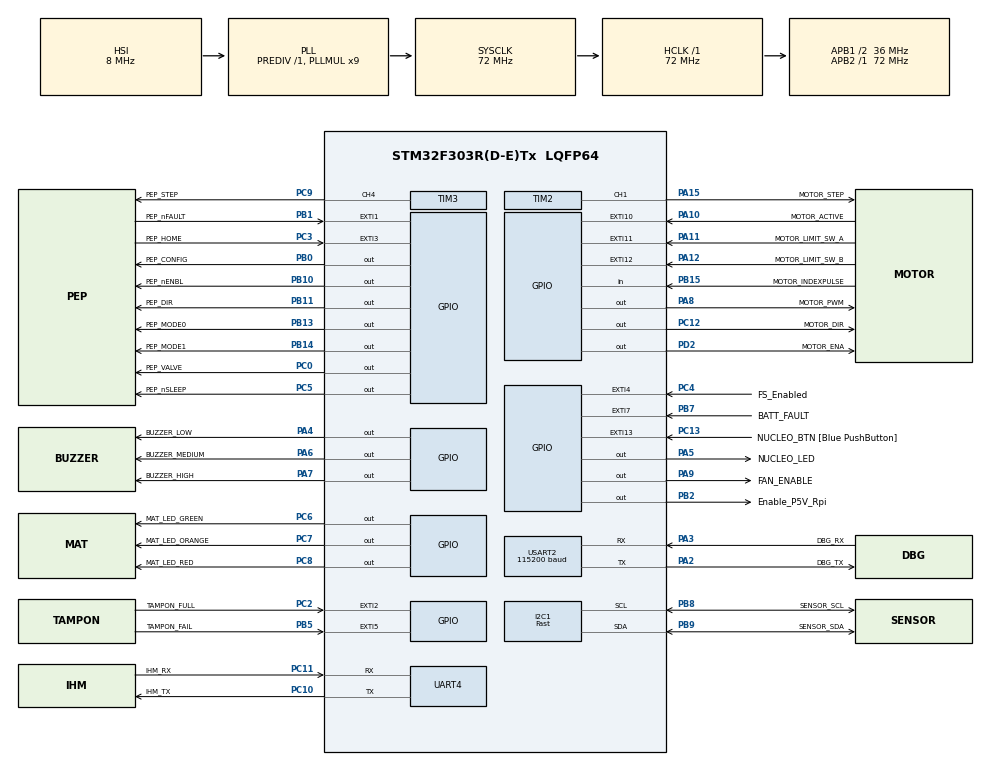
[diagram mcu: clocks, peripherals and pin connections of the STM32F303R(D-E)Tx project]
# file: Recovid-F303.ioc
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Dma.I2C1_RX.0.Direction=DMA_PERIPH_TO_MEMORY
Dma.I2C1_RX.0.Instance=DMA1_Channel7
Dma.I2C1_RX.0.MemDataAlignment=DMA_MDATAALIGN_BYTE
Dma.I2C1_RX.0.MemInc=DMA_MINC_ENABLE
Dma.I2C1_RX.0.Mode=DMA_NORMAL
Dma.I2C1_RX.0.PeriphDataAlignment=DMA_PDATAALIGN_BYTE
Dma.I2C1_RX.0.PeriphInc=DMA_PINC_DISABLE
Dma.I2C1_RX.0.Priority=DMA_PRIORITY_LOW
Dma.I2C1_TX.1.Direction=DMA_MEMORY_TO_PERIPH
Dma.I2C1_TX.1.Instance=DMA1_Channel6
Dma.I2C1_TX.1.MemDataAlignment=DMA_MDATAALIGN_BYTE
Dma.I2C1_TX.1.MemInc=DMA_MINC_ENABLE
Dma.I2C1_TX.1.Mode=DMA_NORMAL
Dma.I2C1_TX.1.PeriphDataAlignment=DMA_PDATAALIGN_BYTE
Dma.I2C1_TX.1.PeriphInc=DMA_PINC_DISABLE
Dma.I2C1_TX.1.Priority=DMA_PRIORITY_LOW
Dma.Request0=I2C1_RX
Dma.Request1=I2C1_TX
Dma.Request2=TIM3_CH4/UP
Dma.Request3=UART4_TX
Dma.Request4=TIM2_UP
Dma.TIM2_UP.4.Direction=DMA_MEMORY_TO_PERIPH
Dma.TIM2_UP.4.Instance=DMA1_Channel2
Dma.TIM2_UP.4.MemDataAlignment=DMA_MDATAALIGN_HALFWORD
Dma.TIM2_UP.4.MemInc=DMA_MINC_ENABLE
Dma.TIM2_UP.4.Mode=DMA_NORMAL
Dma.TIM2_UP.4.PeriphDataAlignment=DMA_PDATAALIGN_WORD
Dma.TIM2_UP.4.PeriphInc=DMA_PINC_DISABLE
Dma.TIM2_UP.4.Priority=DMA_PRIORITY_HIGH
Dma.TIM3_CH4/UP.2.Direction=DMA_PERIPH_TO_MEMORY
Dma.TIM3_CH4/UP.2.Instance=DMA1_Channel3
Dma.TIM3_CH4/UP.2.MemDataAlignment=DMA_MDATAALIGN_HALFWORD
Dma.TIM3_CH4/UP.2.MemInc=DMA_MINC_ENABLE
Dma.TIM3_CH4/UP.2.Mode=DMA_NORMAL
Dma.TIM3_CH4/UP.2.PeriphDataAlignment=DMA_PDATAALIGN_HALFWORD
Dma.TIM3_CH4/UP.2.PeriphInc=DMA_PINC_DISABLE
Dma.TIM3_CH4/UP.2.Priority=DMA_PRIORITY_LOW
Dma.UART4_TX.3.Direction=DMA_MEMORY_TO_PERIPH
Dma.UART4_TX.3.Instance=DMA2_Channel5
Dma.UART4_TX.3.MemDataAlignment=DMA_MDATAALIGN_BYTE
Dma.UART4_TX.3.MemInc=DMA_MINC_ENABLE
Dma.UART4_TX.3.Mode=DMA_NORMAL
Dma.UART4_TX.3.PeriphDataAlignment=DMA_PDATAALIGN_BYTE
Dma.UART4_TX.3.PeriphInc=DMA_PINC_DISABLE
Dma.UART4_TX.3.Priority=DMA_PRIORITY_LOW
I2C1.I2C_Speed_Mode=I2C_Fast
I2C1.Timing=0x0000020B
Mcu.Family=STM32F3
Mcu.Name=STM32F303R(D-E)Tx
Mcu.Package=LQFP64
Mcu.UserConstants=MOTOR_PULSE_WIDTH_US,10;PEP_PULSE_WIDTH_US,10
NVIC.DMA1_Channel2_IRQn=true\:0\:5\:false\:false\:true\:false\:true
NVIC.DMA1_Channel3_IRQn=true\:0\:0\:false\:false\:true\:false\:true
NVIC.DMA1_Channel6_IRQn=true\:0\:0\:false\:false\:true\:false\:true
NVIC.DMA1_Channel7_IRQn=true\:0\:0\:false\:false\:true\:false\:true
NVIC.DMA2_Channel5_IRQn=true\:0\:0\:false\:false\:true\:false\:true
NVIC.EXTI15_10_IRQn=true\:0\:0\:false\:false\:true\:true\:true
NVIC.EXTI1_IRQn=true\:0\:0\:false\:false\:true\:true\:true
NVIC.EXTI2_TSC_IRQn=true\:0\:0\:false\:false\:true\:true\:true
NVIC.EXTI3_IRQn=true\:0\:0\:false\:false\:true\:true\:true
NVIC.EXTI4_IRQn=true\:0\:0\:false\:false\:true\:true\:true
NVIC.EXTI9_5_IRQn=true\:0\:0\:false\:false\:true\:true\:true
NVIC.I2C1_ER_IRQn=true\:0\:0\:false\:false\:true\:true\:true
NVIC.I2C1_EV_IRQn=true\:0\:0\:false\:false\:true\:true\:true
NVIC.PriorityGroup=NVIC_PRIORITYGROUP_0
NVIC.TIM1_BRK_TIM15_IRQn=true\:0\:0\:false\:false\:true\:true\:true
NVIC.TIM2_IRQn=true\:0\:5\:false\:false\:true\:true\:true
NVIC.TIM3_IRQn=true\:0\:0\:false\:false\:true\:true\:true
NVIC.TIM7_IRQn=true\:0\:0\:false\:false\:true\:true\:true
NVIC.UART4_IRQn=true\:0\:0\:false\:false\:true\:true\:true
NVIC.USART2_IRQn=true\:0\:0\:false\:false\:true\:true\:true
PA10.GPIO_Label=MOTOR_ACTIVE
PA10.GPIO_ModeDefaultEXTI=GPIO_MODE_IT_RISING_FALLING
PA10.Signal=GPXTI10
PA11.GPIO_Label=MOTOR_LIMIT_SW_A
PA11.GPIO_ModeDefaultEXTI=GPIO_MODE_IT_RISING_FALLING
PA11.Signal=GPXTI11
PA12.GPIO_Label=MOTOR_LIMIT_SW_B
PA12.GPIO_ModeDefaultEXTI=GPIO_MODE_IT_RISING_FALLING
PA12.Signal=GPXTI12
PA13.GPIO_Label=TMS
PA13.Mode=Trace_Asynchronous_SW
PA13.Signal=SYS_JTMS-SWDIO
PA14.GPIO_Label=TCK
PA14.Mode=Trace_Asynchronous_SW
PA14.Signal=SYS_JTCK-SWCLK
PA15.GPIO_Label=MOTOR_STEP
PA15.Signal=S_TIM2_CH1_ETR
PA2.GPIO_Label=DBG_TX
PA2.GPIO_Mode=GPIO_MODE_AF_PP
PA2.GPIO_PuPd=GPIO_NOPULL
PA2.GPIO_Speed=GPIO_SPEED_FREQ_LOW
PA2.Mode=Asynchronous
PA2.Signal=USART2_TX
PA3.GPIO_Label=DBG_RX
PA3.GPIO_Mode=GPIO_MODE_AF_PP
PA3.GPIO_PuPd=GPIO_NOPULL
PA3.GPIO_Speed=GPIO_SPEED_FREQ_LOW
PA3.Mode=Asynchronous
PA3.Signal=USART2_RX
PA4.GPIO_Label=BUZZER_LOW
PA4.Signal=GPIO_Output
PA5.GPIO_Label=NUCLEO_LED
PA5.Signal=GPIO_Output
PA6.GPIO_Label=BUZZER_MEDIUM
PA6.Signal=GPIO_Output
PA7.GPIO_Label=BUZZER_HIGH
PA7.Signal=GPIO_Output
PA8.GPIO_Label=MOTOR_PWM
PA8.Signal=GPIO_Output
PA9.GPIO_Label=FAN_ENABLE
PA9.Signal=GPIO_Output
PB0.GPIO_Label=PEP_CONFIG
PB0.Signal=GPIO_Output
PB1.GPIO_Label=PEP_nFAULT
PB1.Signal=GPXTI1
PB10.GPIO_Label=PEP_nENBL
PB10.Signal=GPIO_Output
PB11.GPIO_Label=PEP_DIR
PB11.Signal=GPIO_Output
PB13.GPIO_Label=PEP_MODE0
PB13.Signal=GPIO_Output
PB14.GPIO_Label=PEP_MODE1
PB14.Signal=GPIO_Output
PB15.GPIO_Label=MOTOR_INDEXPULSE
PB15.Signal=GPIO_Input
PB2.GPIO_Label=Enable_P5V_Rpi
PB2.Signal=GPIO_Output
PB3.GPIO_Label=SWO
PB3.Mode=Trace_Asynchronous_SW
PB3.Signal=SYS_JTDO-TRACESWO
PB5.GPIO_Label=TAMPON_FAIL
PB5.Signal=GPXTI5
PB7.GPIO_Label=BATT_FAULT
PB7.Signal=GPXTI7
PB8.GPIO_Label=SENSOR_SCL
PB8.Mode=I2C
PB8.Signal=I2C1_SCL
PB9.GPIO_Label=SENSOR_SDA
PB9.Mode=I2C
PB9.Signal=I2C1_SDA
PC0.GPIO_Label=PEP_VALVE
PC0.Signal=GPIO_Output
PC10.GPIO_Label=IHM_TX
PC10.Mode=Asynchronous
PC10.Signal=UART4_TX
PC11.GPIO_Label=IHM_RX
PC11.Mode=Asynchronous
PC11.Signal=UART4_RX
PC12.GPIO_Label=MOTOR_DIR
PC12.Signal=GPIO_Output
PC13.GPIO_Label=NUCLEO_BTN [Blue PushButton]
PC13.GPIO_ModeDefaultEXTI=GPIO_MODE_IT_FALLING
PC13.Signal=GPXTI13
PC14-OSC32_IN.Mode=LSE-External-Oscillator
PC14-OSC32_IN.Signal=RCC_OSC32_IN
PC15-OSC32_OUT.Mode=LSE-External-Oscillator
PC15-OSC32_OUT.Signal=RCC_OSC32_OUT
PC2.GPIO_Label=TAMPON_FULL
PC2.Signal=GPXTI2
PC3.GPIO_Label=PEP_HOME
PC3.GPIO_ModeDefaultEXTI=GPIO_MODE_IT_RISING_FALLING
PC3.Signal=GPXTI3
PC4.GPIO_Label=FS_Enabled
PC4.Signal=GPXTI4
PC5.GPIO_Label=PEP_nSLEEP
PC5.Signal=GPIO_Output
PC6.GPIO_Label=MAT_LED_GREEN
PC6.Signal=GPIO_Output
PC7.GPIO_Label=MAT_LED_ORANGE
PC7.Signal=GPIO_Output
PC8.GPIO_Label=MAT_LED_RED
PC8.Signal=GPIO_Output
PC9.GPIO_Label=PEP_STEP
PC9.Signal=S_TIM3_CH4
PD2.GPIO_Label=MOTOR_ENA
PD2.Signal=GPIO_Output
PF0-OSC_IN.Mode=HSE-External-Clock-Source
PF0-OSC_IN.Signal=RCC_OSC_IN
PF1-OSC_OUT.Signal=RCC_OSC_OUT
ProjectManager.HeapSize=0x200
ProjectManager.StackSize=0x400
ProjectManager.TargetToolchain=STM32CubeIDE
RCC.AHBFreq_Value=72000000
RCC.APB1CLKDivider=RCC_HCLK_DIV2
RCC.APB1Freq_Value=36000000
RCC.APB1TimFreq_Value=72000000
RCC.APB2Freq_Value=72000000
RCC.APB2TimFreq_Value=72000000
RCC.CortexFreq_Value=72000000
RCC.HCLKFreq_Value=72000000
RCC.HSE_VALUE=8000000
RCC.HSI_VALUE=8000000
RCC.PLLM=8
RCC.PLLMUL=RCC_PLL_MUL9
RCC.PLLN=336
RCC.PLLP=RCC_PLLP_DIV4
RCC.PLLQ=7
RCC.RCC_PLLsource_Clock_Source_FROM_HSE=RCC_HSE_PREDIV_DIV2
RCC.SYSCLKFreq_VALUE=72000000
RCC.SYSCLKSourceVirtual=RCC_SYSCLKSOURCE_PLLCLK
RCC.USBFreq_Value=72000000
SH.S_TIM2_CH1_ETR.0=TIM2_CH1,PWM Generation1 CH1
SH.S_TIM3_CH4.0=TIM3_CH4,PWM Generation4 CH4
TIM15.Period=1000
TIM15.Prescaler=72-1
TIM2.Channel-PWM\ Generation1\ CH1=TIM_CHANNEL_1
TIM2.Prescaler=72-1
TIM2.Pulse-PWM\ Generation1\ CH1=5
TIM3.Channel-PWM\ Generation4\ CH4=TIM_CHANNEL_4
TIM3.Prescaler=72-1
TIM3.Pulse-PWM\ Generation4\ CH4=PEP_PULSE_WIDTH_US
TIM4.Period=0xFFFF
TIM4.Prescaler=72-1
TIM7.Period=1000
TIM7.Prescaler=72-1
USART2.BaudRate=115200
USART2.VirtualMode-Asynchronous=VM_ASYNC
VP_TIM15_VS_ClockSourceINT.Mode=Internal
VP_TIM2_VS_ClockSourceINT.Mode=Internal
VP_TIM3_VS_ClockSourceINT.Mode=Internal
VP_TIM4_VS_ClockSourceINT.Mode=Internal
VP_TIM7_VS_ClockSourceINT.Mode=Enable_Timer
board=NUCLEO-F303RE

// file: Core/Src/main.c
/* USER CODE BEGIN Header */
/**
 ******************************************************************************
 * @file           : main.c
 * @brief          : Main program body
 ******************************************************************************
 * @attention
 *
 * <h2><center>&copy; Copyright (c) 2020 STMicroelectronics.
 * All rights reserved.</center></h2>
 *
 * This software component is licensed by ST under BSD 3-Clause license,
 * the "License"; You may not use this file except in compliance with the
 * License. You may obtain a copy of the License at:
 *                        opensource.org/licenses/BSD-3-Clause
 *
 ******************************************************************************
 */
/* USER CODE END Header */

#include "main.h"

/* USER CODE BEGIN Includes */
#include <stdio.h>
#include "controller.h"
/* USER CODE END Includes */

I2C_HandleTypeDef hi2c1;
DMA_HandleTypeDef hdma_i2c1_rx;
DMA_HandleTypeDef hdma_i2c1_tx;

TIM_HandleTypeDef htim2;
TIM_HandleTypeDef htim3;
TIM_HandleTypeDef htim4;
TIM_HandleTypeDef htim7;
TIM_HandleTypeDef htim15;
DMA_HandleTypeDef hdma_tim2_up;
DMA_HandleTypeDef hdma_tim3_ch4_up;

UART_HandleTypeDef huart4;
UART_HandleTypeDef huart2;
DMA_HandleTypeDef hdma_uart4_tx;

void SystemClock_Config(void);
static void MX_GPIO_Init(void);
static void MX_DMA_Init(void);
static void MX_USART2_UART_Init(void);
static void MX_I2C1_Init(void);
static void MX_TIM3_Init(void);
static void MX_TIM4_Init(void);
static void MX_UART4_Init(void);
static void MX_TIM15_Init(void);
static void MX_TIM2_Init(void);
static void MX_TIM7_Init(void);
/* USER CODE BEGIN PFP */

#ifdef __GNUC__
/* With GCC, small printf (option LD Linker->Libraries->Small printf
 set to 'Yes') calls __io_putchar() */
#define PUTCHAR_PROTOTYPE int __io_putchar(int ch)
#else
  #define PUTCHAR_PROTOTYPE int fputc(int ch, FILE *f)
#endif /* __GNUC__ */

/* USER CODE END PFP */

int main(void)
{

  /* MCU Configuration--------------------------------------------------------*/

  /* Reset of all peripherals, Initializes the Flash interface and the Systick. */
  HAL_Init();

  /* Configure the system clock */
  SystemClock_Config();

  /* Initialize all configured peripherals */
  MX_GPIO_Init();
  MX_DMA_Init();
  MX_USART2_UART_Init();
  MX_I2C1_Init();
  MX_TIM3_Init();
  MX_TIM4_Init();
  MX_UART4_Init();
  MX_TIM15_Init();
  MX_TIM2_Init();
  MX_TIM7_Init();
  /* USER CODE BEGIN 2 */

  controller_run();

  /* USER CODE END 2 */

  /* Infinite loop */
	while (1) {

	}
}

void SystemClock_Config(void)
{
  RCC_OscInitTypeDef RCC_OscInitStruct = {0};
  RCC_ClkInitTypeDef RCC_ClkInitStruct = {0};
  RCC_PeriphCLKInitTypeDef PeriphClkInit = {0};

  /** Initializes the CPU, AHB and APB busses clocks
  */
  RCC_OscInitStruct.OscillatorType = RCC_OSCILLATORTYPE_HSI;
  RCC_OscInitStruct.HSIState = RCC_HSI_ON;
  RCC_OscInitStruct.HSICalibrationValue = RCC_HSICALIBRATION_DEFAULT;
  RCC_OscInitStruct.PLL.PLLState = RCC_PLL_ON;
  RCC_OscInitStruct.PLL.PLLSource = RCC_PLLSOURCE_HSI;
  RCC_OscInitStruct.PLL.PLLMUL = RCC_PLL_MUL9;
  RCC_OscInitStruct.PLL.PREDIV = RCC_PREDIV_DIV1;
  if (HAL_RCC_OscConfig(&RCC_OscInitStruct) != HAL_OK)
  {
    Error_Handler();
  }
  /** Initializes the CPU, AHB and APB busses clocks
  */
  RCC_ClkInitStruct.ClockType = RCC_CLOCKTYPE_HCLK|RCC_CLOCKTYPE_SYSCLK
                              |RCC_CLOCKTYPE_PCLK1|RCC_CLOCKTYPE_PCLK2;
  RCC_ClkInitStruct.SYSCLKSource = RCC_SYSCLKSOURCE_PLLCLK;
  RCC_ClkInitStruct.AHBCLKDivider = RCC_SYSCLK_DIV1;
  RCC_ClkInitStruct.APB1CLKDivider = RCC_HCLK_DIV2;
  RCC_ClkInitStruct.APB2CLKDivider = RCC_HCLK_DIV1;

  if (HAL_RCC_ClockConfig(&RCC_ClkInitStruct, FLASH_LATENCY_2) != HAL_OK)
  {
    Error_Handler();
  }
  PeriphClkInit.PeriphClockSelection = RCC_PERIPHCLK_USART2|RCC_PERIPHCLK_UART4
                              |RCC_PERIPHCLK_I2C1|RCC_PERIPHCLK_TIM15
                              |RCC_PERIPHCLK_TIM2|RCC_PERIPHCLK_TIM34;
  PeriphClkInit.Usart2ClockSelection = RCC_USART2CLKSOURCE_PCLK1;
  PeriphClkInit.Uart4ClockSelection = RCC_UART4CLKSOURCE_PCLK1;
  PeriphClkInit.I2c1ClockSelection = RCC_I2C1CLKSOURCE_HSI;
  PeriphClkInit.Tim15ClockSelection = RCC_TIM15CLK_HCLK;
  PeriphClkInit.Tim2ClockSelection = RCC_TIM2CLK_HCLK;
  PeriphClkInit.Tim34ClockSelection = RCC_TIM34CLK_HCLK;
  if (HAL_RCCEx_PeriphCLKConfig(&PeriphClkInit) != HAL_OK)
  {
    Error_Handler();
  }
}

static void MX_I2C1_Init(void)
{

  hi2c1.Instance = I2C1;
  hi2c1.Init.Timing = 0x0000020B;
  hi2c1.Init.OwnAddress1 = 0;
  hi2c1.Init.AddressingMode = I2C_ADDRESSINGMODE_7BIT;
  hi2c1.Init.DualAddressMode = I2C_DUALADDRESS_DISABLE;
  hi2c1.Init.OwnAddress2 = 0;
  hi2c1.Init.OwnAddress2Masks = I2C_OA2_NOMASK;
  hi2c1.Init.GeneralCallMode = I2C_GENERALCALL_DISABLE;
  hi2c1.Init.NoStretchMode = I2C_NOSTRETCH_DISABLE;
  if (HAL_I2C_Init(&hi2c1) != HAL_OK)
  {
    Error_Handler();
  }
  /** Configure Analogue filter
  */
  if (HAL_I2CEx_ConfigAnalogFilter(&hi2c1, I2C_ANALOGFILTER_ENABLE) != HAL_OK)
  {
    Error_Handler();
  }
  /** Configure Digital filter
  */
  if (HAL_I2CEx_ConfigDigitalFilter(&hi2c1, 0) != HAL_OK)
  {
    Error_Handler();
  }

}

static void MX_TIM2_Init(void)
{

  TIM_ClockConfigTypeDef sClockSourceConfig = {0};
  TIM_MasterConfigTypeDef sMasterConfig = {0};
  TIM_OC_InitTypeDef sConfigOC = {0};

  htim2.Instance = TIM2;
  htim2.Init.Prescaler = 72-1;
  htim2.Init.CounterMode = TIM_COUNTERMODE_UP;
  htim2.Init.Period = 0;
  htim2.Init.ClockDivision = TIM_CLOCKDIVISION_DIV1;
  htim2.Init.AutoReloadPreload = TIM_AUTORELOAD_PRELOAD_DISABLE;
  if (HAL_TIM_Base_Init(&htim2) != HAL_OK)
  {
    Error_Handler();
  }
  sClockSourceConfig.ClockSource = TIM_CLOCKSOURCE_INTERNAL;
  if (HAL_TIM_ConfigClockSource(&htim2, &sClockSourceConfig) != HAL_OK)
  {
    Error_Handler();
  }
  if (HAL_TIM_PWM_Init(&htim2) != HAL_OK)
  {
    Error_Handler();
  }
  sMasterConfig.MasterOutputTrigger = TIM_TRGO_RESET;
  sMasterConfig.MasterSlaveMode = TIM_MASTERSLAVEMODE_DISABLE;
  if (HAL_TIMEx_MasterConfigSynchronization(&htim2, &sMasterConfig) != HAL_OK)
  {
    Error_Handler();
  }
  sConfigOC.OCMode = TIM_OCMODE_PWM1;
  sConfigOC.Pulse = 5;
  sConfigOC.OCPolarity = TIM_OCPOLARITY_HIGH;
  sConfigOC.OCFastMode = TIM_OCFAST_DISABLE;
  if (HAL_TIM_PWM_ConfigChannel(&htim2, &sConfigOC, TIM_CHANNEL_1) != HAL_OK)
  {
    Error_Handler();
  }
  HAL_TIM_MspPostInit(&htim2);

}

static void MX_TIM3_Init(void)
{

  TIM_ClockConfigTypeDef sClockSourceConfig = {0};
  TIM_MasterConfigTypeDef sMasterConfig = {0};
  TIM_OC_InitTypeDef sConfigOC = {0};

  htim3.Instance = TIM3;
  htim3.Init.Prescaler = 72-1;
  htim3.Init.CounterMode = TIM_COUNTERMODE_UP;
  htim3.Init.Period = 0;
  htim3.Init.ClockDivision = TIM_CLOCKDIVISION_DIV1;
  htim3.Init.AutoReloadPreload = TIM_AUTORELOAD_PRELOAD_DISABLE;
  if (HAL_TIM_Base_Init(&htim3) != HAL_OK)
  {
    Error_Handler();
  }
  sClockSourceConfig.ClockSource = TIM_CLOCKSOURCE_INTERNAL;
  if (HAL_TIM_ConfigClockSource(&htim3, &sClockSourceConfig) != HAL_OK)
  {
    Error_Handler();
  }
  if (HAL_TIM_PWM_Init(&htim3) != HAL_OK)
  {
    Error_Handler();
  }
  sMasterConfig.MasterOutputTrigger = TIM_TRGO_RESET;
  sMasterConfig.MasterSlaveMode = TIM_MASTERSLAVEMODE_DISABLE;
  if (HAL_TIMEx_MasterConfigSynchronization(&htim3, &sMasterConfig) != HAL_OK)
  {
    Error_Handler();
  }
  sConfigOC.OCMode = TIM_OCMODE_PWM1;
  sConfigOC.Pulse = PEP_PULSE_WIDTH_US;
  sConfigOC.OCPolarity = TIM_OCPOLARITY_HIGH;
  sConfigOC.OCFastMode = TIM_OCFAST_DISABLE;
  if (HAL_TIM_PWM_ConfigChannel(&htim3, &sConfigOC, TIM_CHANNEL_4) != HAL_OK)
  {
    Error_Handler();
  }
  HAL_TIM_MspPostInit(&htim3);

}

static void MX_TIM4_Init(void)
{

  TIM_ClockConfigTypeDef sClockSourceConfig = {0};
  TIM_MasterConfigTypeDef sMasterConfig = {0};

  htim4.Instance = TIM4;
  htim4.Init.Prescaler = 72-1;
  htim4.Init.CounterMode = TIM_COUNTERMODE_UP;
  htim4.Init.Period = 0xFFFF;
  htim4.Init.ClockDivision = TIM_CLOCKDIVISION_DIV1;
  htim4.Init.AutoReloadPreload = TIM_AUTORELOAD_PRELOAD_DISABLE;
  if (HAL_TIM_Base_Init(&htim4) != HAL_OK)
  {
    Error_Handler();
  }
  sClockSourceConfig.ClockSource = TIM_CLOCKSOURCE_INTERNAL;
  if (HAL_TIM_ConfigClockSource(&htim4, &sClockSourceConfig) != HAL_OK)
  {
    Error_Handler();
  }
  sMasterConfig.MasterOutputTrigger = TIM_TRGO_RESET;
  sMasterConfig.MasterSlaveMode = TIM_MASTERSLAVEMODE_DISABLE;
  if (HAL_TIMEx_MasterConfigSynchronization(&htim4, &sMasterConfig) != HAL_OK)
  {
    Error_Handler();
  }

}

static void MX_TIM7_Init(void)
{

  TIM_MasterConfigTypeDef sMasterConfig = {0};

  htim7.Instance = TIM7;
  htim7.Init.Prescaler = 72-1;
  htim7.Init.CounterMode = TIM_COUNTERMODE_UP;
  htim7.Init.Period = 1000;
  htim7.Init.AutoReloadPreload = TIM_AUTORELOAD_PRELOAD_DISABLE;
  if (HAL_TIM_Base_Init(&htim7) != HAL_OK)
  {
    Error_Handler();
  }
  sMasterConfig.MasterOutputTrigger = TIM_TRGO_RESET;
  sMasterConfig.MasterSlaveMode = TIM_MASTERSLAVEMODE_DISABLE;
  if (HAL_TIMEx_MasterConfigSynchronization(&htim7, &sMasterConfig) != HAL_OK)
  {
    Error_Handler();
  }

}

static void MX_TIM15_Init(void)
{

  TIM_ClockConfigTypeDef sClockSourceConfig = {0};
  TIM_MasterConfigTypeDef sMasterConfig = {0};

  htim15.Instance = TIM15;
  htim15.Init.Prescaler = 72-1;
  htim15.Init.CounterMode = TIM_COUNTERMODE_UP;
  htim15.Init.Period = 1000;
  htim15.Init.ClockDivision = TIM_CLOCKDIVISION_DIV1;
  htim15.Init.RepetitionCounter = 0;
  htim15.Init.AutoReloadPreload = TIM_AUTORELOAD_PRELOAD_DISABLE;
  if (HAL_TIM_Base_Init(&htim15) != HAL_OK)
  {
    Error_Handler();
  }
  sClockSourceConfig.ClockSource = TIM_CLOCKSOURCE_INTERNAL;
  if (HAL_TIM_ConfigClockSource(&htim15, &sClockSourceConfig) != HAL_OK)
  {
    Error_Handler();
  }
  sMasterConfig.MasterOutputTrigger = TIM_TRGO_RESET;
  sMasterConfig.MasterSlaveMode = TIM_MASTERSLAVEMODE_DISABLE;
  if (HAL_TIMEx_MasterConfigSynchronization(&htim15, &sMasterConfig) != HAL_OK)
  {
    Error_Handler();
  }

}

static void MX_UART4_Init(void)
{

  huart4.Instance = UART4;
  huart4.Init.BaudRate = 115200;
  huart4.Init.WordLength = UART_WORDLENGTH_8B;
  huart4.Init.StopBits = UART_STOPBITS_1;
  huart4.Init.Parity = UART_PARITY_NONE;
  huart4.Init.Mode = UART_MODE_TX_RX;
  huart4.Init.HwFlowCtl = UART_HWCONTROL_NONE;
  huart4.Init.OverSampling = UART_OVERSAMPLING_16;
  huart4.Init.OneBitSampling = UART_ONE_BIT_SAMPLE_DISABLE;
  huart4.AdvancedInit.AdvFeatureInit = UART_ADVFEATURE_NO_INIT;
  if (HAL_UART_Init(&huart4) != HAL_OK)
  {
    Error_Handler();
  }

}

static void MX_USART2_UART_Init(void)
{

  huart2.Instance = USART2;
  huart2.Init.BaudRate = 115200;
  huart2.Init.WordLength = UART_WORDLENGTH_8B;
  huart2.Init.StopBits = UART_STOPBITS_1;
  huart2.Init.Parity = UART_PARITY_NONE;
  huart2.Init.Mode = UART_MODE_TX_RX;
  huart2.Init.HwFlowCtl = UART_HWCONTROL_NONE;
  huart2.Init.OverSampling = UART_OVERSAMPLING_16;
  huart2.Init.OneBitSampling = UART_ONE_BIT_SAMPLE_DISABLE;
  huart2.AdvancedInit.AdvFeatureInit = UART_ADVFEATURE_NO_INIT;
  if (HAL_UART_Init(&huart2) != HAL_OK)
  {
    Error_Handler();
  }

}

static void MX_DMA_Init(void)
{

  /* DMA controller clock enable */
  __HAL_RCC_DMA1_CLK_ENABLE();
  __HAL_RCC_DMA2_CLK_ENABLE();

  /* DMA interrupt init */
  /* DMA1_Channel2_IRQn interrupt configuration */
  HAL_NVIC_SetPriority(DMA1_Channel2_IRQn, 0, 5);
  HAL_NVIC_EnableIRQ(DMA1_Channel2_IRQn);
  /* DMA1_Channel3_IRQn interrupt configuration */
  HAL_NVIC_SetPriority(DMA1_Channel3_IRQn, 0, 0);
  HAL_NVIC_EnableIRQ(DMA1_Channel3_IRQn);
  /* DMA1_Channel6_IRQn interrupt configuration */
  HAL_NVIC_SetPriority(DMA1_Channel6_IRQn, 0, 0);
  HAL_NVIC_EnableIRQ(DMA1_Channel6_IRQn);
  /* DMA1_Channel7_IRQn interrupt configuration */
  HAL_NVIC_SetPriority(DMA1_Channel7_IRQn, 0, 0);
  HAL_NVIC_EnableIRQ(DMA1_Channel7_IRQn);
  /* DMA2_Channel5_IRQn interrupt configuration */
  HAL_NVIC_SetPriority(DMA2_Channel5_IRQn, 0, 0);
  HAL_NVIC_EnableIRQ(DMA2_Channel5_IRQn);

}

static void MX_GPIO_Init(void)
{
  GPIO_InitTypeDef GPIO_InitStruct = {0};

  /* GPIO Ports Clock Enable */
  __HAL_RCC_GPIOC_CLK_ENABLE();
  __HAL_RCC_GPIOF_CLK_ENABLE();
  __HAL_RCC_GPIOA_CLK_ENABLE();
  __HAL_RCC_GPIOB_CLK_ENABLE();
  __HAL_RCC_GPIOD_CLK_ENABLE();

  /*Configure GPIO pin Output Level */
  HAL_GPIO_WritePin(GPIOC, PEP_VALVE_Pin|PEP_nSLEEP_Pin|MAT_LED_GREEN_Pin|MAT_LED_ORANGE_Pin
                          |MAT_LED_RED_Pin|MOTOR_DIR_Pin, GPIO_PIN_RESET);

  /*Configure GPIO pin Output Level */
  HAL_GPIO_WritePin(GPIOA, BUZZER_LOW_Pin|NUCLEO_LED_Pin|BUZZER_MEDIUM_Pin|BUZZER_HIGH_Pin
                          |MOTOR_PWM_Pin|FAN_ENABLE_Pin, GPIO_PIN_RESET);

  /*Configure GPIO pin Output Level */
  HAL_GPIO_WritePin(GPIOB, PEP_CONFIG_Pin|Enable_P5V_Rpi_Pin|PEP_nENBL_Pin|PEP_DIR_Pin
                          |PEP_MODE0_Pin|PEP_MODE1_Pin, GPIO_PIN_RESET);

  /*Configure GPIO pin Output Level */
  HAL_GPIO_WritePin(MOTOR_ENA_GPIO_Port, MOTOR_ENA_Pin, GPIO_PIN_RESET);

  /*Configure GPIO pin : NUCLEO_BTN_Pin */
  GPIO_InitStruct.Pin = NUCLEO_BTN_Pin;
  GPIO_InitStruct.Mode = GPIO_MODE_IT_FALLING;
  GPIO_InitStruct.Pull = GPIO_NOPULL;
  HAL_GPIO_Init(NUCLEO_BTN_GPIO_Port, &GPIO_InitStruct);

  /*Configure GPIO pins : PEP_VALVE_Pin PEP_nSLEEP_Pin MAT_LED_GREEN_Pin MAT_LED_ORANGE_Pin
                           MAT_LED_RED_Pin MOTOR_DIR_Pin */
  GPIO_InitStruct.Pin = PEP_VALVE_Pin|PEP_nSLEEP_Pin|MAT_LED_GREEN_Pin|MAT_LED_ORANGE_Pin
                          |MAT_LED_RED_Pin|MOTOR_DIR_Pin;
  GPIO_InitStruct.Mode = GPIO_MODE_OUTPUT_PP;
  GPIO_InitStruct.Pull = GPIO_NOPULL;
  GPIO_InitStruct.Speed = GPIO_SPEED_FREQ_LOW;
  HAL_GPIO_Init(GPIOC, &GPIO_InitStruct);

  /*Configure GPIO pins : TAMPON_FULL_Pin FS_Enabled_Pin */
  GPIO_InitStruct.Pin = TAMPON_FULL_Pin|FS_Enabled_Pin;
  GPIO_InitStruct.Mode = GPIO_MODE_IT_RISING;
  GPIO_InitStruct.Pull = GPIO_NOPULL;
  HAL_GPIO_Init(GPIOC, &GPIO_InitStruct);

  /*Configure GPIO pin : PEP_HOME_Pin */
  GPIO_InitStruct.Pin = PEP_HOME_Pin;
  GPIO_InitStruct.Mode = GPIO_MODE_IT_RISING_FALLING;
  GPIO_InitStruct.Pull = GPIO_NOPULL;
  HAL_GPIO_Init(PEP_HOME_GPIO_Port, &GPIO_InitStruct);

  /*Configure GPIO pins : BUZZER_LOW_Pin NUCLEO_LED_Pin BUZZER_MEDIUM_Pin BUZZER_HIGH_Pin
                           MOTOR_PWM_Pin FAN_ENABLE_Pin */
  GPIO_InitStruct.Pin = BUZZER_LOW_Pin|NUCLEO_LED_Pin|BUZZER_MEDIUM_Pin|BUZZER_HIGH_Pin
                          |MOTOR_PWM_Pin|FAN_ENABLE_Pin;
  GPIO_InitStruct.Mode = GPIO_MODE_OUTPUT_PP;
  GPIO_InitStruct.Pull = GPIO_NOPULL;
  GPIO_InitStruct.Speed = GPIO_SPEED_FREQ_LOW;
  HAL_GPIO_Init(GPIOA, &GPIO_InitStruct);

  /*Configure GPIO pins : PEP_CONFIG_Pin Enable_P5V_Rpi_Pin PEP_nENBL_Pin PEP_DIR_Pin
                           PEP_MODE0_Pin PEP_MODE1_Pin */
  GPIO_InitStruct.Pin = PEP_CONFIG_Pin|Enable_P5V_Rpi_Pin|PEP_nENBL_Pin|PEP_DIR_Pin
                          |PEP_MODE0_Pin|PEP_MODE1_Pin;
  GPIO_InitStruct.Mode = GPIO_MODE_OUTPUT_PP;
  GPIO_InitStruct.Pull = GPIO_NOPULL;
  GPIO_InitStruct.Speed = GPIO_SPEED_FREQ_LOW;
  HAL_GPIO_Init(GPIOB, &GPIO_InitStruct);

  /*Configure GPIO pins : PEP_nFAULT_Pin TAMPON_FAIL_Pin BATT_FAULT_Pin */
  GPIO_InitStruct.Pin = PEP_nFAULT_Pin|TAMPON_FAIL_Pin|BATT_FAULT_Pin;
  GPIO_InitStruct.Mode = GPIO_MODE_IT_RISING;
  GPIO_InitStruct.Pull = GPIO_NOPULL;
  HAL_GPIO_Init(GPIOB, &GPIO_InitStruct);

  /*Configure GPIO pin : MOTOR_INDEXPULSE_Pin */
  GPIO_InitStruct.Pin = MOTOR_INDEXPULSE_Pin;
  GPIO_InitStruct.Mode = GPIO_MODE_INPUT;
  GPIO_InitStruct.Pull = GPIO_NOPULL;
  HAL_GPIO_Init(MOTOR_INDEXPULSE_GPIO_Port, &GPIO_InitStruct);

  /*Configure GPIO pins : MOTOR_ACTIVE_Pin MOTOR_LIMIT_SW_A_Pin MOTOR_LIMIT_SW_B_Pin */
  GPIO_InitStruct.Pin = MOTOR_ACTIVE_Pin|MOTOR_LIMIT_SW_A_Pin|MOTOR_LIMIT_SW_B_Pin;
  GPIO_InitStruct.Mode = GPIO_MODE_IT_RISING_FALLING;
  GPIO_InitStruct.Pull = GPIO_NOPULL;
  HAL_GPIO_Init(GPIOA, &GPIO_InitStruct);

  /*Configure GPIO pin : MOTOR_ENA_Pin */
  GPIO_InitStruct.Pin = MOTOR_ENA_Pin;
  GPIO_InitStruct.Mode = GPIO_MODE_OUTPUT_PP;
  GPIO_InitStruct.Pull = GPIO_NOPULL;
  GPIO_InitStruct.Speed = GPIO_SPEED_FREQ_LOW;
  HAL_GPIO_Init(MOTOR_ENA_GPIO_Port, &GPIO_InitStruct);

  /* EXTI interrupt init*/
  HAL_NVIC_SetPriority(EXTI1_IRQn, 0, 0);
  HAL_NVIC_EnableIRQ(EXTI1_IRQn);

  HAL_NVIC_SetPriority(EXTI2_TSC_IRQn, 0, 0);
  HAL_NVIC_EnableIRQ(EXTI2_TSC_IRQn);

  HAL_NVIC_SetPriority(EXTI3_IRQn, 0, 0);
  HAL_NVIC_EnableIRQ(EXTI3_IRQn);

  HAL_NVIC_SetPriority(EXTI4_IRQn, 0, 0);
  HAL_NVIC_EnableIRQ(EXTI4_IRQn);

  HAL_NVIC_SetPriority(EXTI9_5_IRQn, 0, 0);
  HAL_NVIC_EnableIRQ(EXTI9_5_IRQn);

  HAL_NVIC_SetPriority(EXTI15_10_IRQn, 0, 0);
  HAL_NVIC_EnableIRQ(EXTI15_10_IRQn);

}

/* USER CODE BEGIN 4 */

/**
 * @brief  Retargets the C library printf function to the USART.
 * @param  None
 * @retval None
 */
PUTCHAR_PROTOTYPE {
	/* Place your implementation of fputc here */
	/* e.g. write a character to the EVAL_COM1 and Loop until the end of transmission */
	HAL_UART_Transmit(&huart2, (uint8_t*) &ch, 1, 0xFFFF);
//	ITM_SendChar(ch);
	return ch;
}

/* USER CODE END 4 */

void Error_Handler(void)
{
}

/************************ (C) COPYRIGHT STMicroelectronics *****END OF FILE****/
